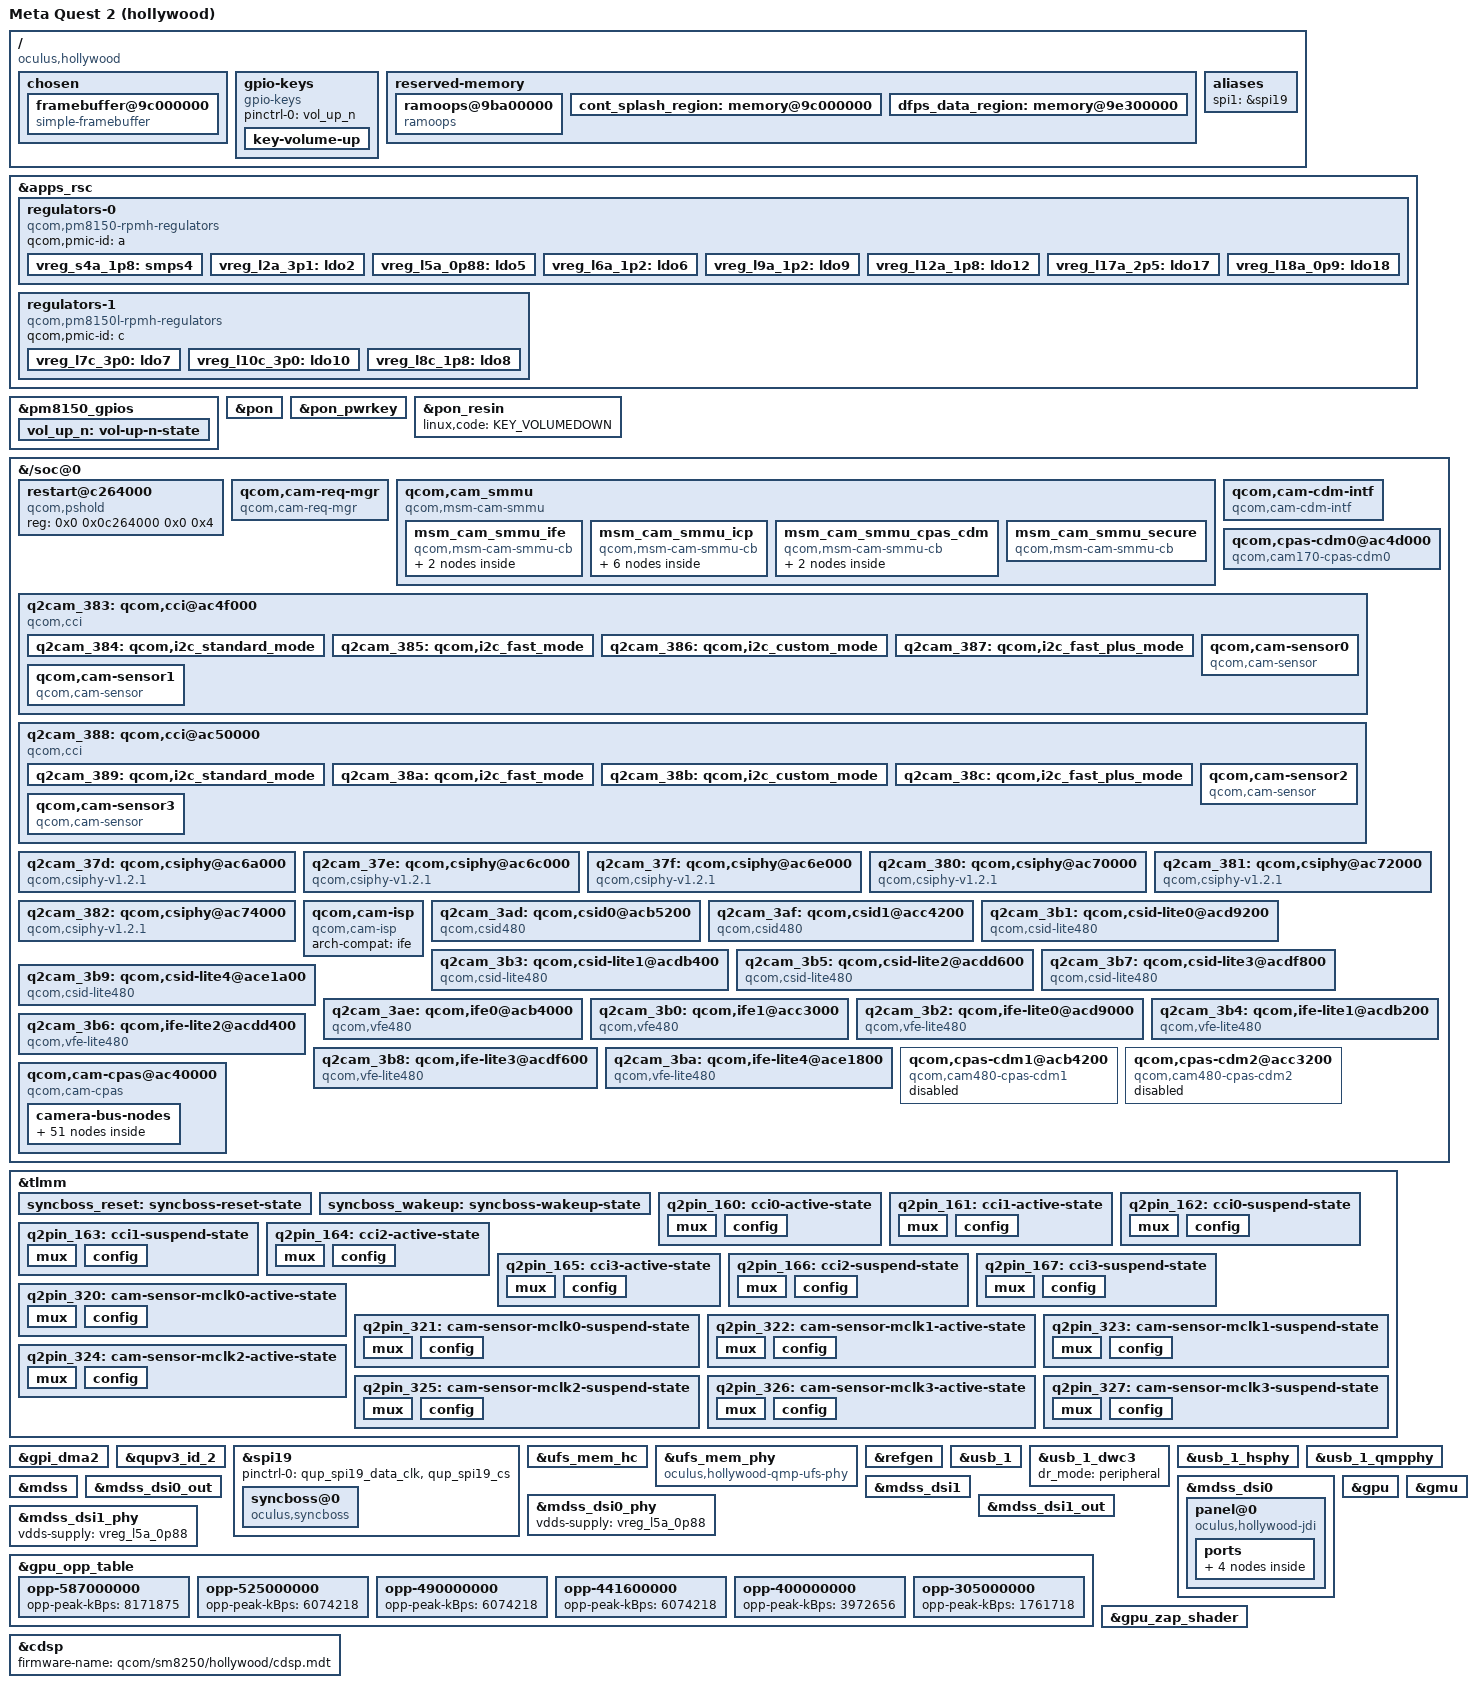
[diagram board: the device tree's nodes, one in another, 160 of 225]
// SPDX-License-Identifier: GPL-2.0-only
/*
 * Meta Quest 2 (hollywood), stage 1: storage, USB device mode, keys and the RAM console.
 * Display, GPU and the rest stay off, as the bootloader left them.
 * Supplies, carve-outs and GPIOs from the Quest 2's stock tree (board "Hollywood (DVT)", 0x40 0x11).
 */

/dts-v1/;

#include <dt-bindings/arm/qcom,ids.h>
#include <dt-bindings/clock/qcom,dispcc-sm8250.h>
#include <dt-bindings/phy/phy.h>
#include <dt-bindings/firmware/qcom,scm.h>
#include <dt-bindings/input/input.h>
#include <dt-bindings/regulator/qcom,rpmh-regulator.h>
#include "sm8250.dtsi"
#include "pm8150.dtsi"
#include "sm8250-oculus-hollywood-dtbo-sink.dtsi"

/ {
	model = "Meta Quest 2 (hollywood)";
	compatible = "oculus,hollywood", "qcom,sm8250";
	chassis-type = "embedded";

	/* Meta's board overlay overwrites compatible and model; the kernel restores them from these. */
	quest2,compatible = "oculus,hollywood", "qcom,sm8250";
	quest2,model = "Meta Quest 2 (hollywood)";

	/* Base tree chosen by SoC revision; the board itself comes from Meta's dtbo. */
	qcom,msm-id = <QCOM_ID_SM8250 0x20001>;
	qcom,board-id = <0 0>;

	chosen {
		#address-cells = <2>;
		#size-cells = <2>;
		ranges;

		/* The bootloader's splash, still scanned out: the kernel console until the display driver runs. */
		framebuffer@9c000000 {
			compatible = "simple-framebuffer";
			reg = <0x0 0x9c000000 0x0 0x1b78000>;
			width = <1920>;
			height = <3664>;
			stride = <7680>;
			format = "a8r8g8b8";
		};
	};

	gpio-keys {
		compatible = "gpio-keys";
		pinctrl-names = "default";
		pinctrl-0 = <&vol_up_n>;

		key-volume-up {
			label = "volume_up";
			gpios = <&pm8150_gpios 6 GPIO_ACTIVE_LOW>;
			linux,code = <KEY_VOLUMEUP>;
			debounce-interval = <15>;
			linux,can-disable;
			wakeup-source;
		};
	};

	reserved-memory {
		/* Same place and size as Quest OS's ramoops. */
		ramoops@9ba00000 {
			compatible = "ramoops";
			reg = <0x0 0x9ba00000 0x0 0x90000>;
			record-size = <0x20000>;
			console-size = <0x40000>;
			pmsg-size = <0x20000>;
			no-map;
		};

		/* Splash framebuffer, still on screen at kernel start. */
		cont_splash_region: memory@9c000000 {
			reg = <0x0 0x9c000000 0x0 0x2300000>;
			no-map;
		};

		dfps_data_region: memory@9e300000 {
			reg = <0x0 0x9e300000 0x0 0x100000>;
			no-map;
		};
	};
};

&apps_rsc {
	regulators-0 {
		compatible = "qcom,pm8150-rpmh-regulators";
		qcom,pmic-id = "a";

		/* UFS and USB supplies, stock voltages. */
		vreg_s4a_1p8: smps4 {
			regulator-name = "vreg_s4a_1p8";
			regulator-min-microvolt = <1800000>;
			regulator-max-microvolt = <1920000>;
		};

		vreg_l2a_3p1: ldo2 {
			regulator-name = "vreg_l2a_3p1";
			regulator-min-microvolt = <3072000>;
			regulator-max-microvolt = <3072000>;
			regulator-initial-mode = <RPMH_REGULATOR_MODE_HPM>;
		};

		vreg_l5a_0p88: ldo5 {
			regulator-name = "vreg_l5a_0p88";
			regulator-min-microvolt = <880000>;
			regulator-max-microvolt = <880000>;
			regulator-initial-mode = <RPMH_REGULATOR_MODE_HPM>;
			/* shared by the UFS and DSI PHYs: a DSI probe error must not switch storage off */
			regulator-always-on;
			regulator-boot-on;
		};

		vreg_l6a_1p2: ldo6 {
			regulator-name = "vreg_l6a_1p2";
			regulator-min-microvolt = <1200000>;
			regulator-max-microvolt = <1200000>;
			regulator-initial-mode = <RPMH_REGULATOR_MODE_HPM>;
		};

		vreg_l9a_1p2: ldo9 {
			regulator-name = "vreg_l9a_1p2";
			regulator-min-microvolt = <1200000>;
			regulator-max-microvolt = <1200000>;
			regulator-initial-mode = <RPMH_REGULATOR_MODE_HPM>;
			/* shared by the UFS and DSI PHYs: a DSI probe error must not switch storage off */
			regulator-always-on;
			regulator-boot-on;
		};

		vreg_l12a_1p8: ldo12 {
			regulator-name = "vreg_l12a_1p8";
			regulator-min-microvolt = <1800000>;
			regulator-max-microvolt = <1800000>;
			regulator-initial-mode = <RPMH_REGULATOR_MODE_HPM>;
		};

		vreg_l17a_2p5: ldo17 {
			regulator-name = "vreg_l17a_2p5";
			/* UFS VCC: UFS 2.1 storage needs 2.7-3.6 V; Quest OS runs it at 2.95 V */
			regulator-min-microvolt = <2952000>;
			regulator-max-microvolt = <2952000>;
			regulator-initial-mode = <RPMH_REGULATOR_MODE_HPM>;
		};

		vreg_l18a_0p9: ldo18 {
			regulator-name = "vreg_l18a_0p9";
			regulator-min-microvolt = <800000>;
			regulator-max-microvolt = <920000>;
			regulator-initial-mode = <RPMH_REGULATOR_MODE_HPM>;
		};
	};

	regulators-1 {
		compatible = "qcom,pm8150l-rpmh-regulators";
		qcom,pmic-id = "c";

		/* SyncBoss' IMU and magnetometer, always on in Quest OS. */
		vreg_l7c_3p0: ldo7 {
			regulator-name = "vreg_l7c_3p0";
			regulator-min-microvolt = <3000000>;
			regulator-max-microvolt = <3000000>;
			regulator-initial-mode = <RPMH_REGULATOR_MODE_HPM>;
			regulator-always-on;
		};

		/* The tracking camera sensors' analog supply (cam_vana), 3.0 V as in Quest OS */
		vreg_l10c_3p0: ldo10 {
			regulator-name = "vreg_l10c_3p0";
			regulator-min-microvolt = <3000000>;
			regulator-max-microvolt = <3000000>;
			regulator-initial-mode = <RPMH_REGULATOR_MODE_HPM>;
		};

		vreg_l8c_1p8: ldo8 {
			regulator-name = "vreg_l8c_1p8";
			regulator-min-microvolt = <1800000>;
			regulator-max-microvolt = <1800000>;
			regulator-initial-mode = <RPMH_REGULATOR_MODE_HPM>;
			regulator-always-on;
		};
	};
};

&pm8150_gpios {
	vol_up_n: vol-up-n-state {
		pins = "gpio6";
		function = "normal";
		power-source = <1>;
		input-enable;
		bias-pull-up;
	};
};

&pon {
	mode-bootloader = <0x2>;
	mode-recovery = <0x1>;
};

&pon_pwrkey {
	status = "okay";
};

&pon_resin {
	linux,code = <KEY_VOLUMEDOWN>;
	status = "okay";
};

/* PS_HOLD reset, as Quest OS does it. */
&{/soc@0} {
	restart@c264000 {
		compatible = "qcom,pshold";
		reg = <0x0 0x0c264000 0x0 0x4>;
	};
};

&tlmm {
	/* GPIOs unused by Quest OS, plus the usual secure lines 28-31 and 40-43. */
	gpio-reserved-ranges = <28 4>, <40 4>, <68 7>, <76 1>, <78 1>, <82 6>, <90 1>, <92 2>,
			       <109 1>, <112 1>, <114 1>, <149 31>;

	syncboss_reset: syncboss-reset-state {
		pins = "gpio5";
		function = "gpio";
		drive-strength = <6>;
		output-low;
	};

	syncboss_wakeup: syncboss-wakeup-state {
		pins = "gpio4";
		function = "gpio";
		bias-pull-down;
		input-enable;
	};
};

/* SyncBoss: Meta's MCU for the IMU, proximity sensor and controller radio (firmware v59), as in Quest OS. */
/* SyncBoss on SPI bus 1 as in Quest OS: Meta's services open /sys/bus/spi/devices/spi1.0/control/te_timestamp. */
/ {
	aliases {
		spi1 = &spi19;
	};
};

&gpi_dma2 {
	status = "okay";
};

&qupv3_id_2 {
	status = "okay";
};

&spi19 {
	pinctrl-names = "default";
	pinctrl-0 = <&qup_spi19_data_clk &qup_spi19_cs>;
	status = "okay";

	syncboss@0 {
		compatible = "oculus,syncboss";
		reg = <0>;
		spi-max-frequency = <8000000>;
		spi-cpol;
		spi-cpha;
		pinctrl-names = "default";
		pinctrl-0 = <&syncboss_reset &syncboss_wakeup>;

		oculus,syncboss-reset-gpios = <&tlmm 5 GPIO_ACTIVE_HIGH>;
		oculus,syncboss-wakeup-gpios = <&tlmm 4 GPIO_ACTIVE_HIGH>;
		oculus,syncboss-timesync-gpios = <&tlmm 66 GPIO_ACTIVE_HIGH>;

		oculus,imu-core-supply = <&vreg_l7c_3p0>;
		oculus,imu-core-voltage-level = <3000000 3000000>;
		oculus,mag-core-supply = <&vreg_l8c_1p8>;
		oculus,mag-core-voltage-level = <1800000 1800000>;

		oculus,syncboss-has-prox;
		oculus,syncboss-use-fastpath;
		oculus,syncboss-has-wake-reasons;
		oculus,syncboss-has-seq-num-ioctl;
	};
};

&ufs_mem_hc {
	status = "okay";

	/* UFS 2.1 storage, gear 3 at most (as Quest OS runs it): the PHY gets its gear-3 tables. */
	limit-hs-gear = <3>;

	/* The storage chip's reset line (the SoC's UFS_RESET pin), pulsed before the link starts. */
	reset-gpios = <&tlmm 180 GPIO_ACTIVE_LOW>;

	vcc-supply = <&vreg_l17a_2p5>;
	vcc-max-microamp = <800000>;
	vccq-supply = <&vreg_l6a_1p2>;
	vccq-max-microamp = <800000>;
	vccq2-supply = <&vreg_s4a_1p8>;
	vccq2-max-microamp = <800000>;
};

&ufs_mem_phy {
	/* UFS 2.1 storage: Quest OS's PHY settings for gear 3 (upstream's are for UFS 3.x) */
	compatible = "oculus,hollywood-qmp-ufs-phy";
	status = "okay";

	vdda-phy-supply = <&vreg_l5a_0p88>;
	vdda-pll-supply = <&vreg_l9a_1p2>;
};

/* The PHYs' shared reference voltage stays on, as the bootloader left it. */
&refgen {
	regulator-always-on;
	regulator-boot-on;
};

&usb_1 {
	status = "okay";
};

/* Stage 1: USB device mode, network to the PC. */
&usb_1_dwc3 {
	dr_mode = "peripheral";
};

&usb_1_hsphy {
	status = "okay";

	vdda-pll-supply = <&vreg_l5a_0p88>;
	vdda18-supply = <&vreg_l12a_1p8>;
	vdda33-supply = <&vreg_l2a_3p1>;
};

&usb_1_qmpphy {
	status = "okay";

	vdda-phy-supply = <&vreg_l9a_1p2>;
	vdda-pll-supply = <&vreg_l18a_0p9>;
};

/* The JDI LCD: both eyes on one panel, two bonded DSI links with DSC. */
&mdss {
	status = "okay";
};

&mdss_dsi0 {
	vdda-supply = <&vreg_l9a_1p2>;
	qcom,dual-dsi-mode;
	qcom,master-dsi;
	status = "okay";

	panel@0 {
		compatible = "oculus,hollywood-jdi";
		reg = <0>;

		enable-gpios = <&tlmm 135 GPIO_ACTIVE_HIGH>;
		reset-gpios = <&tlmm 6 GPIO_ACTIVE_LOW>;

		ports {
			#address-cells = <1>;
			#size-cells = <0>;

			port@0 {
				reg = <0>;
				panel_in0: endpoint {
					remote-endpoint = <&mdss_dsi0_out>;
				};
			};

			port@1 {
				reg = <1>;
				panel_in1: endpoint {
					remote-endpoint = <&mdss_dsi1_out>;
				};
			};
		};
	};
};

&mdss_dsi0_out {
	remote-endpoint = <&panel_in0>;
	data-lanes = <0 1 2 3>;
};

&mdss_dsi0_phy {
	vdds-supply = <&vreg_l5a_0p88>;
	status = "okay";
};

&mdss_dsi1 {
	vdda-supply = <&vreg_l9a_1p2>;
	qcom,dual-dsi-mode;
	assigned-clocks = <&dispcc DISP_CC_MDSS_BYTE1_CLK_SRC>, <&dispcc DISP_CC_MDSS_PCLK1_CLK_SRC>;
	assigned-clock-parents = <&mdss_dsi0_phy DSI_BYTE_PLL_CLK>, <&mdss_dsi0_phy DSI_PIXEL_PLL_CLK>;
	status = "okay";
};

&mdss_dsi1_out {
	remote-endpoint = <&panel_in1>;
	data-lanes = <0 1 2 3>;
};

&mdss_dsi1_phy {
	vdds-supply = <&vreg_l5a_0p88>;
	status = "okay";
};

/* Adreno 650, at most 587 MHz. Memory bandwidth per speed from Quest OS's GPU bus table (ddr7 levels 11/9/7/3). */
&gpu {
	interconnects = <&gem_noc MASTER_GRAPHICS_3D 0 &mc_virt SLAVE_EBI_CH0 0>;
	interconnect-names = "gfx-mem";
	status = "okay";
};

&gmu {
	status = "okay";
};

&gpu_opp_table {
	/delete-node/ opp-670000000;

	opp-587000000 {
		opp-peak-kBps = <8171875>;
	};

	opp-525000000 {
		opp-peak-kBps = <6074218>;
	};

	opp-490000000 {
		opp-peak-kBps = <6074218>;
	};

	opp-441600000 {
		opp-peak-kBps = <6074218>;
	};

	opp-400000000 {
		opp-peak-kBps = <3972656>;
	};

	opp-305000000 {
		opp-peak-kBps = <1761718>;
	};
};

/* This headset's signed zap shader, from its modem partition. */
&gpu_zap_shader {
	firmware-name = "qcom/sm8250/hollywood/a650_zap.mdt";
};

/* The compute DSP (Meta's tracker runs on it), with this headset's own signed firmware from its modem partition. */
&cdsp {
	firmware-name = "qcom/sm8250/hollywood/cdsp.mdt";
	status = "okay";
};

/*
 * Qualcomm's Spectra camera (techpack/camera), nodes converted from Quest OS's own tree: clocks by name onto
 * mainline's gcc/camcc, GDSC supplies as camcc power domains, bus votes on the matching interconnect paths.
 * CPAS: camera power, clocks and bandwidth.
 */
&{/soc@0} {
		/* The request manager: the camera's root device (/dev/video0, media0) the other blocks register under */
		qcom,cam-req-mgr {
			compatible = "qcom,cam-req-mgr";
			status = "okay";
		};

		/* Camera SMMU context banks (IFE, ICP, CPAS CDM) on the apps SMMU with Quest OS's stream ids, and the CDM */
		qcom,cam_smmu {
			compatible = "qcom,msm-cam-smmu";
			status = "ok";
			msm_cam_smmu_ife {
				compatible = "qcom,msm-cam-smmu-cb";
				iommus = <&apps_smmu 0x800 0x400>, <&apps_smmu 0x801 0x400>, <&apps_smmu 0x840 0x400>, <&apps_smmu 0x841 0x400>, <&apps_smmu 0xc00 0x400>, <&apps_smmu 0xc01 0x400>, <&apps_smmu 0xc40 0x400>, <&apps_smmu 0xc41 0x400>;
				qcom,iommu-dma-addr-pool = <0x7400000 0xd8c00000>;
				label = "ife";
				qcom,iommu-faults = "non-fatal";
				q2cam_38d: iova-mem-map {
					iova-mem-region-io {
						iova-region-name = "io";
						iova-region-start = <0x7400000>;
						iova-region-len = <0xd8c00000>;
						iova-region-id = <0x3>;
						status = "ok";
					};
				};
			};
			msm_cam_smmu_icp {
				compatible = "qcom,msm-cam-smmu-cb";
				iommus = <&apps_smmu 0x20e2 0x400>, <&apps_smmu 0x24e2 0x400>, <&apps_smmu 0x2000 0x400>, <&apps_smmu 0x2001 0x400>, <&apps_smmu 0x2400 0x400>, <&apps_smmu 0x2401 0x400>, <&apps_smmu 0x2060 0x400>, <&apps_smmu 0x2061 0x400>, <&apps_smmu 0x2460 0x400>, <&apps_smmu 0x2461 0x400>, <&apps_smmu 0x2020 0x400>, <&apps_smmu 0x2021 0x400>, <&apps_smmu 0x2420 0x400>, <&apps_smmu 0x2421 0x400>;
				label = "icp";
				qcom,iommu-dma-addr-pool = <0x10c00000 0xee300000>;
				iova-region-discard = <0xdff00000 0x300000>;
				qcom,iommu-faults = "non-fatal";
				q2cam_38f: iova-mem-map {
					iova-mem-region-firmware {
						iova-region-name = "firmware";
						iova-region-start = <0x0>;
						iova-region-len = <0x500000>;
						iova-region-id = <0x0>;
						status = "ok";
					};
					iova-mem-region-shared {
						iova-region-name = "shared";
						iova-region-start = <0x7400000>;
						iova-region-len = <0x9600000>;
						iova-region-id = <0x1>;
						status = "ok";
					};
					iova-mem-region-secondary-heap {
						iova-region-name = "secheap";
						iova-region-start = <0x10a00000>;
						iova-region-len = <0x100000>;
						iova-region-id = <0x4>;
						status = "ok";
					};
					iova-mem-region-io {
						iova-region-name = "io";
						iova-region-start = <0x10c00000>;
						iova-region-len = <0xee300000>;
						iova-region-id = <0x3>;
						iova-region-discard = <0xdff00000 0x300000>;
						status = "ok";
					};
					iova-mem-qdss-region {
						iova-region-name = "qdss";
						iova-region-start = <0x10b00000>;
						iova-region-len = <0x100000>;
						iova-region-id = <0x5>;
						qdss-phy-addr = <0x16790000>;
						status = "ok";
					};
				};
			};
			msm_cam_smmu_cpas_cdm {
				compatible = "qcom,msm-cam-smmu-cb";
				iommus = <&apps_smmu 0x20c0 0x400>, <&apps_smmu 0x24c0 0x400>;
				label = "cpas-cdm0";
				qcom,iommu-dma-addr-pool = <0x7400000 0xd8c00000>;
				qcom,iommu-faults = "non-fatal";
				q2cam_390: iova-mem-map {
					iova-mem-region-io {
						iova-region-name = "io";
						iova-region-start = <0x7400000>;
						iova-region-len = <0xd8c00000>;
						iova-region-id = <0x3>;
						status = "ok";
					};
				};
			};
			/* The secure bank: no stream ids, only the handle the ISP manager looks up (secure mode unused) */
			msm_cam_smmu_secure {
				compatible = "qcom,msm-cam-smmu-cb";
				label = "cam-secure";
				qcom,secure-cb;
			};
		};
		qcom,cam-cdm-intf {
			compatible = "qcom,cam-cdm-intf";
			cell-index = <0x0>;
			label = "cam-cdm-intf";
			num-hw-cdm = <0x3>;
			cdm-client-names = "vfe", "vife";
			status = "ok";
		};
		qcom,cpas-cdm0@ac4d000 {
			cell-index = <0x0>;
			compatible = "qcom,cam170-cpas-cdm0";
			label = "cpas-cdm";
			reg = <0x0 0xac4d000 0x0 0x1000>;
			reg-names = "cpas-cdm";
			reg-cam-base = <0x4d000>;
			interrupts = <0x0 0x1cd 0x1>;
			interrupt-names = "cpas-cdm";
			regulator-names = "camss";
			clock-names = "cam_cc_cpas_slow_ahb_clk", "cam_cc_cpas_ahb_clk";
			clocks = <&camcc CAM_CC_SLOW_AHB_CLK_SRC>, <&camcc CAM_CC_CPAS_AHB_CLK>;
			clock-rates = <0x0 0x0>;
			clock-cntl-level = "svs";
			cdm-client-names = "ife";
			status = "ok";
			power-domains = <&camcc TITAN_TOP_GDSC>;
			power-domain-names = "camss";
		};

		/* CCI (camera I2C) with the four tracking camera sensors behind it, as Quest OS's tree has them */
		q2cam_383: qcom,cci@ac4f000 {
			cell-index = <0x0>;
			compatible = "qcom,cci";
			reg = <0x0 0xac4f000 0x0 0x1000>;
			reg-names = "cci";
			reg-cam-base = <0x4f000>;
			interrupt-names = "cci";
			interrupts = <0x0 0x1cc 0x1>;
			status = "ok";
			regulator-names = "gdscr";
			clocks = <&camcc CAM_CC_CCI_0_CLK_SRC>, <&camcc CAM_CC_CCI_0_CLK>;
			clock-names = "cci_0_clk_src", "cci_0_clk";
			src-clock-name = "cci_0_clk_src";
			clock-cntl-level = "lowsvs";
			clock-rates = <0x23c3460 0x0>;
			pinctrl-names = "cam_default", "cam_suspend";
			pinctrl-0 = <&q2pin_160 &q2pin_161>;
			pinctrl-1 = <&q2pin_162 &q2pin_163>;
			gpios = <&tlmm 101 0>, <&tlmm 102 0>, <&tlmm 103 0>, <&tlmm 104 0>;
			gpio-req-tbl-num = <0x0 0x1 0x2 0x3>;
			gpio-req-tbl-flags = <0x1 0x1 0x1 0x1>;
			gpio-req-tbl-label = "CCI_I2C_DATA0", "CCI_I2C_CLK0", "CCI_I2C_DATA1", "CCI_I2C_CLK1";
			power-domains = <&camcc TITAN_TOP_GDSC>;
			power-domain-names = "gdscr";
			q2cam_384: qcom,i2c_standard_mode {
				hw-thigh = <0xc9>;
				hw-tlow = <0xae>;
				hw-tsu-sto = <0xcc>;
				hw-tsu-sta = <0xe7>;
				hw-thd-dat = <0x16>;
				hw-thd-sta = <0xa2>;
				hw-tbuf = <0xe3>;
				hw-scl-stretch-en = <0x0>;
				hw-trdhld = <0x6>;
				hw-tsp = <0x3>;
				cci-clk-src = <0x23c3460>;
				status = "ok";
			};
			q2cam_385: qcom,i2c_fast_mode {
				hw-thigh = <0x26>;
				hw-tlow = <0x38>;
				hw-tsu-sto = <0x28>;
				hw-tsu-sta = <0x28>;
				hw-thd-dat = <0x16>;
				hw-thd-sta = <0x23>;
				hw-tbuf = <0x3e>;
				hw-scl-stretch-en = <0x0>;
				hw-trdhld = <0x6>;
				hw-tsp = <0x3>;
				cci-clk-src = <0x23c3460>;
				status = "ok";
			};
			q2cam_386: qcom,i2c_custom_mode {
				hw-thigh = <0x26>;
				hw-tlow = <0x38>;
				hw-tsu-sto = <0x28>;
				hw-tsu-sta = <0x28>;
				hw-thd-dat = <0x16>;
				hw-thd-sta = <0x23>;
				hw-tbuf = <0x3e>;
				hw-scl-stretch-en = <0x1>;
				hw-trdhld = <0x6>;
				hw-tsp = <0x3>;
				cci-clk-src = <0x23c3460>;
				status = "ok";
			};
			q2cam_387: qcom,i2c_fast_plus_mode {
				hw-thigh = <0x10>;
				hw-tlow = <0x16>;
				hw-tsu-sto = <0x11>;
				hw-tsu-sta = <0x12>;
				hw-thd-dat = <0x10>;
				hw-thd-sta = <0xf>;
				hw-tbuf = <0x18>;
				hw-scl-stretch-en = <0x0>;
				hw-trdhld = <0x3>;
				hw-tsp = <0x3>;
				cci-clk-src = <0x23c3460>;
				status = "ok";
			};
			qcom,cam-sensor0 {
				cell-index = <0x0>;
				compatible = "qcom,cam-sensor";
				csiphy-sd-index = <0x2>;
				sensor-position-roll = <0x5a>;
				sensor-position-pitch = <0x0>;
				sensor-position-yaw = <0xb4>;
				cam_vana-supply = <&vreg_l10c_3p0>;
				cam_vio-supply = <&vreg_s4a_1p8>;
				regulator-names = "cam_vana", "cam_vio", "cam_clk";
				rgltr-cntrl-support;
				pwm-switch;
				rgltr-min-voltage = <0x2dc6c0 0x1b7740 0x0>;
				rgltr-max-voltage = <0x2dc6c0 0x1b7740 0x0>;
				rgltr-load-current = <0x1d4c0 0x13880 0x0>;
				gpio-no-mux = <0x0>;
				pinctrl-names = "cam_default", "cam_suspend";
				pinctrl-0 = <&q2pin_324>;
				pinctrl-1 = <&q2pin_325>;
				gpios = <&tlmm 96 0>;
				gpio-req-tbl-num = <0x0>;
				gpio-req-tbl-flags = <0x1>;
				gpio-req-tbl-label = "CAMIF_MCLK2";
				sensor-mode = <0x0>;
				cci-master = <0x0>;
				status = "ok";
				clocks = <&camcc CAM_CC_MCLK2_CLK>;
				clock-names = "cam_clk";
				clock-cntl-level = "turbo";
				clock-rates = <0x16e3600>;
				power-domains = <&camcc TITAN_TOP_GDSC>;
				power-domain-names = "cam_clk";
			};
			qcom,cam-sensor1 {
				cell-index = <0x1>;
				compatible = "qcom,cam-sensor";
				csiphy-sd-index = <0x1>;
				sensor-position-roll = <0x5a>;
				sensor-position-pitch = <0x0>;
				sensor-position-yaw = <0xb4>;
				cam_vana-supply = <&vreg_l10c_3p0>;
				cam_vio-supply = <&vreg_s4a_1p8>;
				regulator-names = "cam_vana", "cam_vio", "cam_clk";
				rgltr-cntrl-support;
				pwm-switch;
				rgltr-min-voltage = <0x2dc6c0 0x1b7740 0x0>;
				rgltr-max-voltage = <0x2dc6c0 0x1b7740 0x0>;
				rgltr-load-current = <0x1d4c0 0x13880 0x0>;
				gpio-no-mux = <0x0>;
				pinctrl-names = "cam_default", "cam_suspend";
				pinctrl-0 = <&q2pin_326>;
				pinctrl-1 = <&q2pin_327>;
				gpios = <&tlmm 95 0>;
				gpio-req-tbl-num = <0x0>;
				gpio-req-tbl-flags = <0x1>;
				gpio-req-tbl-label = "CAMIF_MCLK1";
				sensor-mode = <0x0>;
				cci-master = <0x1>;
				status = "ok";
				clocks = <&camcc CAM_CC_MCLK1_CLK>;
				clock-names = "cam_clk";
				clock-cntl-level = "turbo";
				clock-rates = <0x16e3600>;
				power-domains = <&camcc TITAN_TOP_GDSC>;
				power-domain-names = "cam_clk";
			};
		};
		q2cam_388: qcom,cci@ac50000 {
			cell-index = <0x1>;
			compatible = "qcom,cci";
			reg = <0x0 0xac50000 0x0 0x1000>;
			reg-names = "cci";
			reg-cam-base = <0x50000>;
			interrupt-names = "cci";
			interrupts = <0x0 0x10f 0x1>;
			status = "ok";
			regulator-names = "gdscr";
			clocks = <&camcc CAM_CC_CCI_1_CLK_SRC>, <&camcc CAM_CC_CCI_1_CLK>;
			clock-names = "cci_1_clk_src", "cci_1_clk";
			src-clock-name = "cci_1_clk_src";
			clock-cntl-level = "lowsvs";
			clock-rates = <0x23c3460 0x0>;
			pinctrl-names = "cam_default", "cam_suspend";
			pinctrl-0 = <&q2pin_164 &q2pin_165>;
			pinctrl-1 = <&q2pin_166 &q2pin_167>;
			gpios = <&tlmm 105 0>, <&tlmm 106 0>, <&tlmm 107 0>, <&tlmm 108 0>;
			gpio-req-tbl-num = <0x0 0x1 0x2 0x3>;
			gpio-req-tbl-flags = <0x1 0x1 0x1 0x1>;
			gpio-req-tbl-label = "CCI_I2C_DATA2", "CCI_I2C_CLK2", "CCI_I2C_DATA3", "CCI_I2C_CLK3";
			power-domains = <&camcc TITAN_TOP_GDSC>;
			power-domain-names = "gdscr";
			q2cam_389: qcom,i2c_standard_mode {
				hw-thigh = <0xc9>;
				hw-tlow = <0xae>;
				hw-tsu-sto = <0xcc>;
				hw-tsu-sta = <0xe7>;
				hw-thd-dat = <0x16>;
				hw-thd-sta = <0xa2>;
				hw-tbuf = <0xe3>;
				hw-scl-stretch-en = <0x0>;
				hw-trdhld = <0x6>;
				hw-tsp = <0x3>;
				cci-clk-src = <0x23c3460>;
				status = "ok";
			};
			q2cam_38a: qcom,i2c_fast_mode {
				hw-thigh = <0x26>;
				hw-tlow = <0x38>;
				hw-tsu-sto = <0x28>;
				hw-tsu-sta = <0x28>;
				hw-thd-dat = <0x16>;
				hw-thd-sta = <0x23>;
				hw-tbuf = <0x3e>;
				hw-scl-stretch-en = <0x0>;
				hw-trdhld = <0x6>;
				hw-tsp = <0x3>;
				cci-clk-src = <0x23c3460>;
				status = "ok";
			};
			q2cam_38b: qcom,i2c_custom_mode {
				hw-thigh = <0x26>;
				hw-tlow = <0x38>;
				hw-tsu-sto = <0x28>;
				hw-tsu-sta = <0x28>;
				hw-thd-dat = <0x16>;
				hw-thd-sta = <0x23>;
				hw-tbuf = <0x3e>;
				hw-scl-stretch-en = <0x1>;
				hw-trdhld = <0x6>;
				hw-tsp = <0x3>;
				cci-clk-src = <0x23c3460>;
				status = "ok";
			};
			q2cam_38c: qcom,i2c_fast_plus_mode {
				hw-thigh = <0x10>;
				hw-tlow = <0x16>;
				hw-tsu-sto = <0x11>;
				hw-tsu-sta = <0x12>;
				hw-thd-dat = <0x10>;
				hw-thd-sta = <0xf>;
				hw-tbuf = <0x18>;
				hw-scl-stretch-en = <0x0>;
				hw-trdhld = <0x3>;
				hw-tsp = <0x3>;
				cci-clk-src = <0x23c3460>;
				status = "ok";
			};
			qcom,cam-sensor2 {
				cell-index = <0x2>;
				compatible = "qcom,cam-sensor";
				csiphy-sd-index = <0x0>;
				sensor-position-roll = <0x10e>;
				sensor-position-pitch = <0x0>;
				sensor-position-yaw = <0x0>;
				cam_vana-supply = <&vreg_l10c_3p0>;
				cam_vio-supply = <&vreg_s4a_1p8>;
				regulator-names = "cam_vana", "cam_vio", "cam_clk";
				rgltr-cntrl-support;
				pwm-switch;
				rgltr-min-voltage = <0x2dc6c0 0x1b7740 0x0>;
				rgltr-max-voltage = <0x2dc6c0 0x1b7740 0x0>;
				rgltr-load-current = <0x1d4c0 0x13880 0x0>;
				gpio-no-mux = <0x0>;
				pinctrl-names = "cam_default", "cam_suspend";
				pinctrl-0 = <&q2pin_320>;
				pinctrl-1 = <&q2pin_321>;
				gpios = <&tlmm 94 0>;
				gpio-req-tbl-num = <0x0>;
				gpio-req-tbl-flags = <0x1>;
				gpio-req-tbl-label = "CAMIF_MCLK0";
				sensor-mode = <0x0>;
				cci-master = <0x0>;
				status = "ok";
				clocks = <&camcc CAM_CC_MCLK0_CLK>;
				clock-names = "cam_clk";
				clock-cntl-level = "turbo";
				clock-rates = <0x16e3600>;
				power-domains = <&camcc TITAN_TOP_GDSC>;
				power-domain-names = "cam_clk";
			};
			qcom,cam-sensor3 {
				cell-index = <0x3>;
				compatible = "qcom,cam-sensor";
				csiphy-sd-index = <0x3>;
				sensor-position-roll = <0x10e>;
				sensor-position-pitch = <0x0>;
				sensor-position-yaw = <0x0>;
				cam_vana-supply = <&vreg_l10c_3p0>;
				cam_vio-supply = <&vreg_s4a_1p8>;
				regulator-names = "cam_vana", "cam_vio", "cam_clk";
				rgltr-cntrl-support;
				rgltr-min-voltage = <0x2dc6c0 0x1b7740 0x0>;
				rgltr-max-voltage = <0x2dc6c0 0x1b7740 0x0>;
				rgltr-load-current = <0x1d4c0 0x13880 0x0>;
				gpio-no-mux = <0x0>;
				pinctrl-names = "cam_default", "cam_suspend";
				pinctrl-0 = <&q2pin_322>;
				pinctrl-1 = <&q2pin_323>;
				gpios = <&tlmm 97 0>;
				gpio-req-tbl-num = <0x0>;
				gpio-req-tbl-flags = <0x1>;
				gpio-req-tbl-label = "CAMIF_MCLK3";
				sensor-mode = <0x0>;
				cci-master = <0x1>;
				status = "ok";
				clocks = <&camcc CAM_CC_MCLK3_CLK>;
				clock-names = "cam_clk";
				clock-cntl-level = "turbo";
				clock-rates = <0x16e3600>;
				power-domains = <&camcc TITAN_TOP_GDSC>;
				power-domain-names = "cam_clk";
			};
		};

		/* CSIPHYs, the ISP (IFE0/1 + five IFE-lites with their CSIDs) and the IFE CDMs */
		q2cam_37d: qcom,csiphy@ac6a000 {
			cell-index = <0x0>;
			compatible = "qcom,csiphy-v1.2.1", "qcom,csiphy";
			reg = <0x0 0xac6a000 0x0 0x2000>;
			reg-names = "csiphy";
			reg-cam-base = <0x6a000>;
			interrupts = <0x0 0x1dd 0x1>;
			interrupt-names = "csiphy";
			refgen-supply = <&refgen>;
			regulator-names = "gdscr", "refgen";
			csi-vdd-voltage = <0x124f80>;
			mipi-csi-vdd-supply = <&vreg_l9a_1p2>;
			clocks = <&camcc CAM_CC_CPHY_RX_CLK_SRC>, <&camcc CAM_CC_CSIPHY0_CLK>, <&camcc CAM_CC_CSI0PHYTIMER_CLK_SRC>, <&camcc CAM_CC_CSI0PHYTIMER_CLK>;
			clock-names = "cphy_rx_clk_src", "csiphy0_clk", "csi0phytimer_clk_src", "csi0phytimer_clk";
			src-clock-name = "csi0phytimer_clk_src";
			clock-cntl-level = "turbo";
			clock-rates = <0x17d78400 0x0 0x11e1a300 0x0>;
			status = "ok";
			power-domains = <&camcc TITAN_TOP_GDSC>;
			power-domain-names = "gdscr";
		};
		q2cam_37e: qcom,csiphy@ac6c000 {
			cell-index = <0x1>;
			compatible = "qcom,csiphy-v1.2.1", "qcom,csiphy";
			reg = <0x0 0xac6c000 0x0 0x2000>;
			reg-names = "csiphy";
			reg-cam-base = <0x6c000>;
			interrupts = <0x0 0x1de 0x1>;
			interrupt-names = "csiphy";
			refgen-supply = <&refgen>;
			regulator-names = "gdscr", "refgen";
			csi-vdd-voltage = <0x124f80>;
			mipi-csi-vdd-supply = <&vreg_l9a_1p2>;
			clocks = <&camcc CAM_CC_CPHY_RX_CLK_SRC>, <&camcc CAM_CC_CSIPHY1_CLK>, <&camcc CAM_CC_CSI1PHYTIMER_CLK_SRC>, <&camcc CAM_CC_CSI1PHYTIMER_CLK>;
			clock-names = "cphy_rx_clk_src", "csiphy1_clk", "csi1phytimer_clk_src", "csi1phytimer_clk";
			src-clock-name = "csi1phytimer_clk_src";
			clock-cntl-level = "turbo";
			clock-rates = <0x17d78400 0x0 0x11e1a300 0x0>;
			status = "ok";
			power-domains = <&camcc TITAN_TOP_GDSC>;
			power-domain-names = "gdscr";
		};
		q2cam_37f: qcom,csiphy@ac6e000 {
			cell-index = <0x2>;
			compatible = "qcom,csiphy-v1.2.1", "qcom,csiphy";
			reg = <0x0 0xac6e000 0x0 0x2000>;
			reg-names = "csiphy";
			reg-cam-base = <0x6e000>;
			interrupts = <0x0 0x1df 0x1>;
			interrupt-names = "csiphy";
			refgen-supply = <&refgen>;
			regulator-names = "gdscr", "refgen";
			csi-vdd-voltage = <0x124f80>;
			mipi-csi-vdd-supply = <&vreg_l9a_1p2>;
			clocks = <&camcc CAM_CC_CPHY_RX_CLK_SRC>, <&camcc CAM_CC_CSIPHY2_CLK>, <&camcc CAM_CC_CSI2PHYTIMER_CLK_SRC>, <&camcc CAM_CC_CSI2PHYTIMER_CLK>;
			clock-names = "cphy_rx_clk_src", "csiphy2_clk", "csi2phytimer_clk_src", "csi2phytimer_clk";
			src-clock-name = "csi2phytimer_clk_src";
			clock-cntl-level = "turbo";
			clock-rates = <0x17d78400 0x0 0x11e1a300 0x0>;
			status = "ok";
			power-domains = <&camcc TITAN_TOP_GDSC>;
			power-domain-names = "gdscr";
		};
		q2cam_380: qcom,csiphy@ac70000 {
			cell-index = <0x3>;
			compatible = "qcom,csiphy-v1.2.1", "qcom,csiphy";
			reg = <0x0 0xac70000 0x0 0x2000>;
			reg-names = "csiphy";
			reg-cam-base = <0x70000>;
			interrupts = <0x0 0x1c0 0x1>;
			interrupt-names = "csiphy";
			refgen-supply = <&refgen>;
			regulator-names = "gdscr", "refgen";
			csi-vdd-voltage = <0x124f80>;
			mipi-csi-vdd-supply = <&vreg_l9a_1p2>;
			clocks = <&camcc CAM_CC_CPHY_RX_CLK_SRC>, <&camcc CAM_CC_CSIPHY3_CLK>, <&camcc CAM_CC_CSI3PHYTIMER_CLK_SRC>, <&camcc CAM_CC_CSI3PHYTIMER_CLK>;
			clock-names = "cphy_rx_clk_src", "csiphy3_clk", "csi3phytimer_clk_src", "csi3phytimer_clk";
			src-clock-name = "csi3phytimer_clk_src";
			clock-cntl-level = "turbo";
			clock-rates = <0x17d78400 0x0 0x11e1a300 0x0>;
			status = "ok";
			power-domains = <&camcc TITAN_TOP_GDSC>;
			power-domain-names = "gdscr";
		};
		q2cam_381: qcom,csiphy@ac72000 {
			cell-index = <0x4>;
			compatible = "qcom,csiphy-v1.2.1", "qcom,csiphy";
			reg = <0x0 0xac72000 0x0 0x2000>;
			reg-names = "csiphy";
			reg-cam-base = <0x72000>;
			interrupts = <0x0 0x56 0x1>;
			interrupt-names = "csiphy";
			refgen-supply = <&refgen>;
			regulator-names = "gdscr", "refgen";
			csi-vdd-voltage = <0x124f80>;
			mipi-csi-vdd-supply = <&vreg_l9a_1p2>;
			clocks = <&camcc CAM_CC_CPHY_RX_CLK_SRC>, <&camcc CAM_CC_CSIPHY4_CLK>, <&camcc CAM_CC_CSI4PHYTIMER_CLK_SRC>, <&camcc CAM_CC_CSI4PHYTIMER_CLK>;
			clock-names = "cphy_rx_clk_src", "csiphy4_clk", "csi4phytimer_clk_src", "csi4phytimer_clk";
			src-clock-name = "csi4phytimer_clk_src";
			clock-cntl-level = "turbo";
			clock-rates = <0x17d78400 0x0 0x11e1a300 0x0>;
			status = "ok";
			power-domains = <&camcc TITAN_TOP_GDSC>;
			power-domain-names = "gdscr";
		};
		q2cam_382: qcom,csiphy@ac74000 {
			cell-index = <0x5>;
			compatible = "qcom,csiphy-v1.2.1", "qcom,csiphy";
			reg = <0x0 0xac74000 0x0 0x2000>;
			reg-names = "csiphy";
			reg-cam-base = <0x74000>;
			interrupts = <0x0 0x59 0x1>;
			interrupt-names = "csiphy";
			refgen-supply = <&refgen>;
			regulator-names = "gdscr", "refgen";
			csi-vdd-voltage = <0x124f80>;
			mipi-csi-vdd-supply = <&vreg_l9a_1p2>;
			clocks = <&camcc CAM_CC_CPHY_RX_CLK_SRC>, <&camcc CAM_CC_CSIPHY5_CLK>, <&camcc CAM_CC_CSI5PHYTIMER_CLK_SRC>, <&camcc CAM_CC_CSI5PHYTIMER_CLK>;
			clock-names = "cphy_rx_clk_src", "csiphy5_clk", "csi5phytimer_clk_src", "csi5phytimer_clk";
			src-clock-name = "csi5phytimer_clk_src";
			clock-cntl-level = "turbo";
			clock-rates = <0x17d78400 0x0 0x11e1a300 0x0>;
			status = "ok";
			power-domains = <&camcc TITAN_TOP_GDSC>;
			power-domain-names = "gdscr";
		};
		qcom,cam-isp {
			compatible = "qcom,cam-isp";
			arch-compat = "ife";
			status = "ok";
		};
		q2cam_3ad: qcom,csid0@acb5200 {
			cell-index = <0x0>;
			compatible = "qcom,csid480";
			reg-names = "csid";
			reg = <0x0 0xacb5200 0x0 0x1000>;
			reg-cam-base = <0xb5200>;
			interrupt-names = "csid";
			interrupts = <0x0 0x1d0 0x1>;
			regulator-names = "camss", "ife0";
			clock-names = "ife_csid_clk_src", "ife_csid_clk", "cphy_rx_clk_src", "ife_cphy_rx_clk", "ife_clk_src", "ife_clk", "ife_0_areg", "ife_0_ahb", "ife_axi_clk";
			clocks = <&camcc CAM_CC_IFE_0_CSID_CLK_SRC>, <&camcc CAM_CC_IFE_0_CSID_CLK>, <&camcc CAM_CC_CPHY_RX_CLK_SRC>, <&camcc CAM_CC_IFE_0_CPHY_RX_CLK>, <&camcc CAM_CC_IFE_0_CLK_SRC>, <&camcc CAM_CC_IFE_0_CLK>, <&camcc CAM_CC_IFE_0_AREG_CLK>, <&camcc CAM_CC_IFE_0_AHB_CLK>, <&camcc CAM_CC_IFE_0_AXI_CLK>;
			clock-rates = <0x17d78400 0x0 0x17d78400 0x0 0x14dc9380 0x0 0x5f5e100 0x0 0x0 0x17d78400 0x0 0x17d78400 0x0 0x1c4fecc0 0x0 0xbebc200 0x0 0x0 0x17d78400 0x0 0x17d78400 0x0 0x22551000 0x0 0x11e1a300 0x0 0x0 0x17d78400 0x0 0x17d78400 0x0 0x2aea5400 0x0 0x17d78400 0x0 0x0>;
			clock-cntl-level = "lowsvs", "svs", "svs_l1", "turbo";
			src-clock-name = "ife_csid_clk_src";
			clock-control-debugfs = "true";
			status = "ok";
			power-domains = <&camcc TITAN_TOP_GDSC>, <&camcc IFE_0_GDSC>;
			power-domain-names = "camss", "ife0";
		};
		q2cam_3af: qcom,csid1@acc4200 {
			cell-index = <0x1>;
			compatible = "qcom,csid480";
			reg-names = "csid";
			reg = <0x0 0xacc4200 0x0 0x1000>;
			reg-cam-base = <0xc4200>;
			interrupt-names = "csid";
			interrupts = <0x0 0x1d2 0x1>;
			regulator-names = "camss", "ife1";
			clock-names = "ife_csid_clk_src", "ife_csid_clk", "cphy_rx_clk_src", "ife_cphy_rx_clk", "ife_clk_src", "ife_clk", "ife_1_areg", "ife_1_ahb", "ife_axi_clk";
			clocks = <&camcc CAM_CC_IFE_1_CSID_CLK_SRC>, <&camcc CAM_CC_IFE_1_CSID_CLK>, <&camcc CAM_CC_CPHY_RX_CLK_SRC>, <&camcc CAM_CC_IFE_1_CPHY_RX_CLK>, <&camcc CAM_CC_IFE_1_CLK_SRC>, <&camcc CAM_CC_IFE_1_CLK>, <&camcc CAM_CC_IFE_1_AREG_CLK>, <&camcc CAM_CC_IFE_1_AHB_CLK>, <&camcc CAM_CC_IFE_1_AXI_CLK>;
			clock-rates = <0x17d78400 0x0 0x17d78400 0x0 0x14dc9380 0x0 0x5f5e100 0x0 0x0 0x17d78400 0x0 0x17d78400 0x0 0x1c4fecc0 0x0 0xbebc200 0x0 0x0 0x17d78400 0x0 0x17d78400 0x0 0x22551000 0x0 0x11e1a300 0x0 0x0 0x17d78400 0x0 0x17d78400 0x0 0x2aea5400 0x0 0x17d78400 0x0 0x0>;
			clock-cntl-level = "lowsvs", "svs", "svs_l1", "turbo";
			src-clock-name = "ife_csid_clk_src";
			clock-control-debugfs = "true";
			status = "ok";
			power-domains = <&camcc TITAN_TOP_GDSC>, <&camcc IFE_1_GDSC>;
			power-domain-names = "camss", "ife1";
		};
		q2cam_3b1: qcom,csid-lite0@acd9200 {
			cell-index = <0x2>;
			compatible = "qcom,csid-lite480";
			reg-names = "csid-lite";
			reg = <0x0 0xacd9200 0x0 0x1000>;
			reg-cam-base = <0xd9200>;
			interrupt-names = "csid-lite";
			interrupts = <0x0 0x1d4 0x1>;
			regulator-names = "camss";
			clock-names = "ife_csid_clk_src", "ife_csid_clk", "cphy_rx_clk_src", "ife_cphy_rx_clk", "ife_clk_src", "ife_lite_ahb", "ife_clk";
			clocks = <&camcc CAM_CC_IFE_LITE_CSID_CLK_SRC>, <&camcc CAM_CC_IFE_LITE_CSID_CLK>, <&camcc CAM_CC_CPHY_RX_CLK_SRC>, <&camcc CAM_CC_IFE_LITE_CPHY_RX_CLK>, <&camcc CAM_CC_IFE_LITE_CLK_SRC>, <&camcc CAM_CC_IFE_LITE_AHB_CLK>, <&camcc CAM_CC_IFE_LITE_CLK>;
			clock-rates = <0x17d78400 0x0 0x0 0x0 0x17d78400 0x0 0x0 0x17d78400 0x0 0x0 0x0 0x1c9c3800 0x0 0x0 0x17d78400 0x0 0x0 0x0 0x1c9c3800 0x0 0x0 0x17d78400 0x0 0x0 0x0 0x1c9c3800 0x0 0x0>;
			clock-cntl-level = "lowsvs", "svs", "svs_l1", "turbo";
			src-clock-name = "ife_csid_clk_src";
			clock-control-debugfs = "true";
			status = "ok";
			power-domains = <&camcc TITAN_TOP_GDSC>;
			power-domain-names = "camss";
		};
		q2cam_3b3: qcom,csid-lite1@acdb400 {
			cell-index = <0x3>;
			compatible = "qcom,csid-lite480";
			reg-names = "csid-lite";
			reg = <0x0 0xacdb400 0x0 0x1000>;
			reg-cam-base = <0xdb400>;
			interrupt-names = "csid-lite";
			interrupts = <0x0 0x167 0x1>;
			regulator-names = "camss";
			clock-names = "ife_csid_clk_src", "ife_csid_clk", "cphy_rx_clk_src", "ife_cphy_rx_clk", "ife_clk_src", "ife_lite_ahb", "ife_clk";
			clocks = <&camcc CAM_CC_IFE_LITE_CSID_CLK_SRC>, <&camcc CAM_CC_IFE_LITE_CSID_CLK>, <&camcc CAM_CC_CPHY_RX_CLK_SRC>, <&camcc CAM_CC_IFE_LITE_CPHY_RX_CLK>, <&camcc CAM_CC_IFE_LITE_CLK_SRC>, <&camcc CAM_CC_IFE_LITE_AHB_CLK>, <&camcc CAM_CC_IFE_LITE_CLK>;
			clock-rates = <0x17d78400 0x0 0x0 0x0 0x17d78400 0x0 0x0 0x17d78400 0x0 0x0 0x0 0x1c9c3800 0x0 0x0 0x17d78400 0x0 0x0 0x0 0x1c9c3800 0x0 0x0 0x17d78400 0x0 0x0 0x0 0x1c9c3800 0x0 0x0>;
			clock-cntl-level = "lowsvs", "svs", "svs_l1", "turbo";
			src-clock-name = "ife_csid_clk_src";
			clock-control-debugfs = "true";
			status = "ok";
			power-domains = <&camcc TITAN_TOP_GDSC>;
			power-domain-names = "camss";
		};
		q2cam_3b5: qcom,csid-lite2@acdd600 {
			cell-index = <0x4>;
			compatible = "qcom,csid-lite480";
			reg-names = "csid-lite";
			reg = <0x0 0xacdd600 0x0 0x1000>;
			reg-cam-base = <0xdd600>;
			interrupt-names = "csid-lite";
			interrupts = <0x0 0x1c1 0x1>;
			regulator-names = "camss";
			clock-names = "ife_csid_clk_src", "ife_csid_clk", "cphy_rx_clk_src", "ife_cphy_rx_clk", "ife_clk_src", "ife_lite_ahb", "ife_clk";
			clocks = <&camcc CAM_CC_IFE_LITE_CSID_CLK_SRC>, <&camcc CAM_CC_IFE_LITE_CSID_CLK>, <&camcc CAM_CC_CPHY_RX_CLK_SRC>, <&camcc CAM_CC_IFE_LITE_CPHY_RX_CLK>, <&camcc CAM_CC_IFE_LITE_CLK_SRC>, <&camcc CAM_CC_IFE_LITE_AHB_CLK>, <&camcc CAM_CC_IFE_LITE_CLK>;
			clock-rates = <0x17d78400 0x0 0x0 0x0 0x17d78400 0x0 0x0 0x17d78400 0x0 0x0 0x0 0x1c9c3800 0x0 0x0 0x17d78400 0x0 0x0 0x0 0x1c9c3800 0x0 0x0 0x17d78400 0x0 0x0 0x0 0x1c9c3800 0x0 0x0>;
			clock-cntl-level = "lowsvs", "svs", "svs_l1", "turbo";
			src-clock-name = "ife_csid_clk_src";
			clock-control-debugfs = "true";
			status = "ok";
			power-domains = <&camcc TITAN_TOP_GDSC>;
			power-domain-names = "camss";
		};
		q2cam_3b7: qcom,csid-lite3@acdf800 {
			cell-index = <0x5>;
			compatible = "qcom,csid-lite480";
			reg-names = "csid-lite";
			reg = <0x0 0xacdf800 0x0 0x1000>;
			reg-cam-base = <0xdf800>;
			interrupt-names = "csid-lite";
			interrupts = <0x0 0x1c3 0x1>;
			regulator-names = "camss";
			clock-names = "ife_csid_clk_src", "ife_csid_clk", "cphy_rx_clk_src", "ife_cphy_rx_clk", "ife_clk_src", "ife_lite_ahb", "ife_clk";
			clocks = <&camcc CAM_CC_IFE_LITE_CSID_CLK_SRC>, <&camcc CAM_CC_IFE_LITE_CSID_CLK>, <&camcc CAM_CC_CPHY_RX_CLK_SRC>, <&camcc CAM_CC_IFE_LITE_CPHY_RX_CLK>, <&camcc CAM_CC_IFE_LITE_CLK_SRC>, <&camcc CAM_CC_IFE_LITE_AHB_CLK>, <&camcc CAM_CC_IFE_LITE_CLK>;
			clock-rates = <0x17d78400 0x0 0x0 0x0 0x17d78400 0x0 0x0 0x17d78400 0x0 0x0 0x0 0x1c9c3800 0x0 0x0 0x17d78400 0x0 0x0 0x0 0x1c9c3800 0x0 0x0 0x17d78400 0x0 0x0 0x0 0x1c9c3800 0x0 0x0>;
			clock-cntl-level = "lowsvs", "svs", "svs_l1", "turbo";
			src-clock-name = "ife_csid_clk_src";
			clock-control-debugfs = "true";
			status = "ok";
			power-domains = <&camcc TITAN_TOP_GDSC>;
			power-domain-names = "camss";
		};
		q2cam_3b9: qcom,csid-lite4@ace1a00 {
			cell-index = <0x6>;
			compatible = "qcom,csid-lite480";
			reg-names = "csid-lite";
			reg = <0x0 0xace1a00 0x0 0x1000>;
			reg-cam-base = <0xe1a00>;
			interrupt-names = "csid-lite";
			interrupts = <0x0 0x1c5 0x1>;
			regulator-names = "camss";
			clock-names = "ife_csid_clk_src", "ife_csid_clk", "cphy_rx_clk_src", "ife_cphy_rx_clk", "ife_clk_src", "ife_lite_ahb", "ife_clk";
			clocks = <&camcc CAM_CC_IFE_LITE_CSID_CLK_SRC>, <&camcc CAM_CC_IFE_LITE_CSID_CLK>, <&camcc CAM_CC_CPHY_RX_CLK_SRC>, <&camcc CAM_CC_IFE_LITE_CPHY_RX_CLK>, <&camcc CAM_CC_IFE_LITE_CLK_SRC>, <&camcc CAM_CC_IFE_LITE_AHB_CLK>, <&camcc CAM_CC_IFE_LITE_CLK>;
			clock-rates = <0x17d78400 0x0 0x0 0x0 0x17d78400 0x0 0x0 0x17d78400 0x0 0x0 0x0 0x1c9c3800 0x0 0x0 0x17d78400 0x0 0x0 0x0 0x1c9c3800 0x0 0x0 0x17d78400 0x0 0x0 0x0 0x1c9c3800 0x0 0x0>;
			clock-cntl-level = "lowsvs", "svs", "svs_l1", "turbo";
			src-clock-name = "ife_csid_clk_src";
			clock-control-debugfs = "true";
			status = "ok";
			power-domains = <&camcc TITAN_TOP_GDSC>;
			power-domain-names = "camss";
		};
		q2cam_3ae: qcom,ife0@acb4000 {
			cell-index = <0x0>;
			compatible = "qcom,vfe480";
			reg-names = "ife", "cam_camnoc";
			reg = <0x0 0xacb4000 0x0 0xd000 0x0 0xac42000 0x0 0x8000>;
			reg-cam-base = <0xb4000 0x42000>;
			interrupt-names = "ife";
			interrupts = <0x0 0x1d1 0x1>;
			regulator-names = "camss", "ife0";
			clock-names = "ife_0_ahb", "ife_0_areg", "ife_clk_src", "ife_clk", "ife_axi_clk";
			clocks = <&camcc CAM_CC_IFE_0_AHB_CLK>, <&camcc CAM_CC_IFE_0_AREG_CLK>, <&camcc CAM_CC_IFE_0_CLK_SRC>, <&camcc CAM_CC_IFE_0_CLK>, <&camcc CAM_CC_IFE_0_AXI_CLK>;
			clock-rates = <0x0 0x5f5e100 0x14dc9380 0x0 0x0 0x0 0xbebc200 0x1c4fecc0 0x0 0x0 0x0 0x11e1a300 0x22551000 0x0 0x0 0x0 0x17d78400 0x2aea5400 0x0 0x0>;
			clock-cntl-level = "lowsvs", "svs", "svs_l1", "turbo";
			src-clock-name = "ife_clk_src";
			scl-clk-names = "ife_0_areg";
			clock-control-debugfs = "true";
			clock-names-option = "ife_dsp_clk";
			clocks-option = <0x58 0x31>;
			clock-rates-option = <0x2aea5400>;
			ubwc-static-cfg = <0x1026 0x1036>;
			status = "ok";
			power-domains = <&camcc TITAN_TOP_GDSC>, <&camcc IFE_0_GDSC>;
			power-domain-names = "camss", "ife0";
		};
		q2cam_3b0: qcom,ife1@acc3000 {
			cell-index = <0x1>;
			compatible = "qcom,vfe480";
			reg-names = "ife", "cam_camnoc";
			reg = <0x0 0xacc3000 0x0 0xd000 0x0 0xac42000 0x0 0x8000>;
			reg-cam-base = <0xc3000 0x42000>;
			interrupt-names = "ife";
			interrupts = <0x0 0x1d3 0x1>;
			regulator-names = "camss", "ife1";
			clock-names = "ife_1_ahb", "ife_1_areg", "ife_clk_src", "ife_clk", "ife_axi_clk";
			clocks = <&camcc CAM_CC_IFE_1_AHB_CLK>, <&camcc CAM_CC_IFE_1_AREG_CLK>, <&camcc CAM_CC_IFE_1_CLK_SRC>, <&camcc CAM_CC_IFE_1_CLK>, <&camcc CAM_CC_IFE_1_AXI_CLK>;
			clock-rates = <0x0 0x5f5e100 0x14dc9380 0x0 0x0 0x0 0xbebc200 0x1c4fecc0 0x0 0x0 0x0 0x11e1a300 0x22551000 0x0 0x0 0x0 0x17d78400 0x2aea5400 0x0 0x0>;
			clock-cntl-level = "lowsvs", "svs", "svs_l1", "turbo";
			src-clock-name = "ife_clk_src";
			scl-clk-names = "ife_1_areg";
			clock-control-debugfs = "true";
			clock-names-option = "ife_dsp_clk";
			clocks-option = <0x58 0x3a>;
			clock-rates-option = <0x2aea5400>;
			ubwc-static-cfg = <0x1026 0x1036>;
			status = "ok";
			power-domains = <&camcc TITAN_TOP_GDSC>, <&camcc IFE_1_GDSC>;
			power-domain-names = "camss", "ife1";
		};
		q2cam_3b2: qcom,ife-lite0@acd9000 {
			cell-index = <0x2>;
			compatible = "qcom,vfe-lite480";
			reg-names = "ife-lite";
			reg = <0x0 0xacd9000 0x0 0x2200>;
			reg-cam-base = <0xd9000>;
			interrupt-names = "ife-lite";
			interrupts = <0x0 0x1d5 0x1>;
			regulator-names = "camss";
			clock-names = "ife_lite_ahb", "ife_lite_axi", "ife_clk_src", "ife_clk";
			clocks = <&camcc CAM_CC_IFE_LITE_AHB_CLK>, <&camcc CAM_CC_IFE_LITE_AXI_CLK>, <&camcc CAM_CC_IFE_LITE_CLK_SRC>, <&camcc CAM_CC_IFE_LITE_CLK>;
			clock-rates = <0x0 0x0 0x17d78400 0x0 0x0 0x0 0x1c9c3800 0x0 0x0 0x0 0x1c9c3800 0x0 0x0 0x0 0x1c9c3800 0x0>;
			clock-cntl-level = "lowsvs", "svs", "svs_l1", "turbo";
			src-clock-name = "ife_clk_src";
			clock-control-debugfs = "true";
			status = "ok";
			power-domains = <&camcc TITAN_TOP_GDSC>;
			power-domain-names = "camss";
		};
		q2cam_3b4: qcom,ife-lite1@acdb200 {
			cell-index = <0x3>;
			compatible = "qcom,vfe-lite480";
			reg-names = "ife-lite";
			reg = <0x0 0xacdb200 0x0 0x2200>;
			reg-cam-base = <0xdb200>;
			interrupt-names = "ife-lite";
			interrupts = <0x0 0x168 0x1>;
			regulator-names = "camss";
			clock-names = "ife_lite_ahb", "ife_lite_axi", "ife_clk_src", "ife_clk";
			clocks = <&camcc CAM_CC_IFE_LITE_AHB_CLK>, <&camcc CAM_CC_IFE_LITE_AXI_CLK>, <&camcc CAM_CC_IFE_LITE_CLK_SRC>, <&camcc CAM_CC_IFE_LITE_CLK>;
			clock-rates = <0x0 0x0 0x17d78400 0x0 0x0 0x0 0x1c9c3800 0x0 0x0 0x0 0x1c9c3800 0x0 0x0 0x0 0x1c9c3800 0x0>;
			clock-cntl-level = "lowsvs", "svs", "svs_l1", "turbo";
			src-clock-name = "ife_clk_src";
			clock-control-debugfs = "true";
			status = "ok";
			power-domains = <&camcc TITAN_TOP_GDSC>;
			power-domain-names = "camss";
		};
		q2cam_3b6: qcom,ife-lite2@acdd400 {
			cell-index = <0x4>;
			compatible = "qcom,vfe-lite480";
			reg-names = "ife-lite";
			reg = <0x0 0xacdd400 0x0 0x2200>;
			reg-cam-base = <0xdd400>;
			interrupt-names = "ife-lite";
			interrupts = <0x0 0x10a 0x1>;
			regulator-names = "camss";
			clock-names = "ife_lite_ahb", "ife_lite_axi", "ife_clk_src", "ife_clk";
			clocks = <&camcc CAM_CC_IFE_LITE_AHB_CLK>, <&camcc CAM_CC_IFE_LITE_AXI_CLK>, <&camcc CAM_CC_IFE_LITE_CLK_SRC>, <&camcc CAM_CC_IFE_LITE_CLK>;
			clock-rates = <0x0 0x0 0x17d78400 0x0 0x0 0x0 0x1c9c3800 0x0 0x0 0x0 0x1c9c3800 0x0 0x0 0x0 0x1c9c3800 0x0>;
			clock-cntl-level = "lowsvs", "svs", "svs_l1", "turbo";
			src-clock-name = "ife_clk_src";
			clock-control-debugfs = "true";
			status = "ok";
			power-domains = <&camcc TITAN_TOP_GDSC>;
			power-domain-names = "camss";
		};
		q2cam_3b8: qcom,ife-lite3@acdf600 {
			cell-index = <0x5>;
			compatible = "qcom,vfe-lite480";
			reg-names = "ife-lite";
			reg = <0x0 0xacdf600 0x0 0x2200>;
			reg-cam-base = <0xdf600>;
			interrupt-names = "ife-lite";
			interrupts = <0x0 0x1c2 0x1>;
			regulator-names = "camss";
			clock-names = "ife_lite_ahb", "ife_lite_axi", "ife_clk_src", "ife_clk";
			clocks = <&camcc CAM_CC_IFE_LITE_AHB_CLK>, <&camcc CAM_CC_IFE_LITE_AXI_CLK>, <&camcc CAM_CC_IFE_LITE_CLK_SRC>, <&camcc CAM_CC_IFE_LITE_CLK>;
			clock-rates = <0x0 0x0 0x17d78400 0x0 0x0 0x0 0x1c9c3800 0x0 0x0 0x0 0x1c9c3800 0x0 0x0 0x0 0x1c9c3800 0x0>;
			clock-cntl-level = "lowsvs", "svs", "svs_l1", "turbo";
			src-clock-name = "ife_clk_src";
			clock-control-debugfs = "true";
			status = "ok";
			power-domains = <&camcc TITAN_TOP_GDSC>;
			power-domain-names = "camss";
		};
		q2cam_3ba: qcom,ife-lite4@ace1800 {
			cell-index = <0x6>;
			compatible = "qcom,vfe-lite480";
			reg-names = "ife-lite";
			reg = <0x0 0xace1800 0x0 0x2200>;
			reg-cam-base = <0xe1800>;
			interrupt-names = "ife-lite";
			interrupts = <0x0 0x1c4 0x1>;
			regulator-names = "camss";
			clock-names = "ife_lite_ahb", "ife_lite_axi", "ife_clk_src", "ife_clk";
			clocks = <&camcc CAM_CC_IFE_LITE_AHB_CLK>, <&camcc CAM_CC_IFE_LITE_AXI_CLK>, <&camcc CAM_CC_IFE_LITE_CLK_SRC>, <&camcc CAM_CC_IFE_LITE_CLK>;
			clock-rates = <0x0 0x0 0x17d78400 0x0 0x0 0x0 0x1c9c3800 0x0 0x0 0x0 0x1c9c3800 0x0 0x0 0x0 0x1c9c3800 0x0>;
			clock-cntl-level = "lowsvs", "svs", "svs_l1", "turbo";
			src-clock-name = "ife_clk_src";
			clock-control-debugfs = "true";
			status = "ok";
			power-domains = <&camcc TITAN_TOP_GDSC>;
			power-domain-names = "camss";
		};
		qcom,cpas-cdm1@acb4200 {
			cell-index = <0x1>;
			compatible = "qcom,cam480-cpas-cdm1";
			label = "cpas-cdm";
			reg = <0x0 0xacb4200 0x0 0x1000>;
			reg-names = "cpas-cdm";
			reg-cam-base = <0xb4200>;
			interrupts = <0x0 0x1c8 0x1>;
			interrupt-names = "cpas-cdm";
			regulator-names = "camss";
			clock-names = "cam_cc_cpas_slow_ahb_clk", "cam_cc_cpas_ahb_clk";
			clocks = <&camcc CAM_CC_SLOW_AHB_CLK_SRC>, <&camcc CAM_CC_CPAS_AHB_CLK>;
			clock-rates = <0x0 0x0>;
			clock-cntl-level = "svs";
			cdm-client-names = "ife0";
			status = "disabled";
			power-domains = <&camcc TITAN_TOP_GDSC>;
			power-domain-names = "camss";
		};
		qcom,cpas-cdm2@acc3200 {
			cell-index = <0x2>;
			compatible = "qcom,cam480-cpas-cdm2";
			label = "cpas-cdm";
			reg = <0x0 0xacc3200 0x0 0x1000>;
			reg-names = "cpas-cdm";
			reg-cam-base = <0xc3200>;
			interrupts = <0x0 0x11f 0x1>;
			interrupt-names = "cpas-cdm";
			regulator-names = "camss";
			clock-names = "cam_cc_cpas_slow_ahb_clk", "cam_cc_cpas_ahb_clk";
			clocks = <&camcc CAM_CC_SLOW_AHB_CLK_SRC>, <&camcc CAM_CC_CPAS_AHB_CLK>;
			clock-rates = <0x0 0x0>;
			clock-cntl-level = "svs";
			cdm-client-names = "ife1";
			status = "disabled";
			power-domains = <&camcc TITAN_TOP_GDSC>;
			power-domain-names = "camss";
		};

		qcom,cam-cpas@ac40000 {
			cell-index = <0x0>;
			compatible = "qcom,cam-cpas";
			label = "cpas";
			arch-compat = "cpas_top";
			status = "okay";
			reg-names = "cam_cpas_top", "cam_camnoc";
			reg = <0x0 0xac40000 0x0 0x1000 0x0 0xac42000 0x0 0x8000>;
			reg-cam-base = <0x40000 0x42000>;
			interrupt-names = "cpas_camnoc";
			interrupts = <0x0 0x1cb 0x1>;
			camnoc-axi-min-ib-bw = <0xb2d05e00>;
			regulator-names = "camss-vdd";
			clock-names = "gcc_ahb_clk", "gcc_axi_hf_clk", "gcc_axi_sf_clk", "slow_ahb_clk_src", "cpas_ahb_clk", "cpas_core_ahb_clk", "camnoc_axi_clk_src", "camnoc_axi_clk";
			/* gcc_ahb_clk: always on in mainline gcc (not handed out); the board XO stands in */
			clocks = <&xo_board>, <&gcc GCC_CAMERA_HF_AXI_CLK>, <&gcc GCC_CAMERA_SF_AXI_CLK>, <&camcc CAM_CC_SLOW_AHB_CLK_SRC>, <&camcc CAM_CC_CPAS_AHB_CLK>, <&camcc CAM_CC_CORE_AHB_CLK>, <&camcc CAM_CC_CAMNOC_AXI_CLK_SRC>, <&camcc CAM_CC_CAMNOC_AXI_CLK>;
			src-clock-name = "camnoc_axi_clk_src";
			clock-rates = <0x0 0x0 0x0 0x0 0x0 0x0 0x0 0x0 0x0 0x0 0x0 0x124f800 0x0 0x0 0x124f800 0x0 0x0 0x0 0x0 0x4c4b400 0x0 0x0 0x11e1a300 0x0 0x0 0x0 0x0 0x4c4b400 0x0 0x0 0x17d78400 0x0 0x0 0x0 0x0 0x4c4b400 0x0 0x0 0x17d78400 0x0 0x0 0x0 0x0 0x4c4b400 0x0 0x0 0x17d78400 0x0 0x0 0x0 0x0 0x4c4b400 0x0 0x0 0x17d78400 0x0 0x0 0x0 0x0 0x4c4b400 0x0 0x0 0x1c9c3800 0x0>;
			clock-cntl-level = "suspend", "minsvs", "lowsvs", "svs", "svs_l1", "nominal", "nominal_l1", "turbo";
			control-camnoc-axi-clk;
			camnoc-bus-width = <0x20>;
			camnoc-axi-clk-bw-margin-perc = <0x14>;
			qcom,msm-bus,name = "cam_ahb";
			qcom,msm-bus,num-cases = <0x8>;
			qcom,msm-bus,num-paths = <0x1>;
			qcom,msm-bus,vectors-KBps = <0x1 0x24d 0x0 0x0 0x1 0x24d 0x0 0x12c00 0x1 0x24d 0x0 0x12c00 0x1 0x24d 0x0 0x249f0 0x1 0x24d 0x0 0x249f0 0x1 0x24d 0x0 0x493e0 0x1 0x24d 0x0 0x493e0 0x1 0x24d 0x0 0x493e0>;
			vdd-corners = <0x10 0x30 0x40 0x80 0xc0 0x100 0x140 0x150 0x180 0x1a0>;
			vdd-corner-ahb-mapping = "suspend", "minsvs", "lowsvs", "svs", "svs_l1", "nominal", "nominal", "nominal", "turbo", "turbo";
			client-id-based;
			client-names = "csiphy0", "csiphy1", "csiphy2", "csiphy3", "csiphy4", "csiphy5", "cci0", "cci1", "csid0", "csid1", "csid2", "csid3", "csid4", "csid5", "csid6", "ife0", "ife1", "ife2", "ife3", "ife4", "ife5", "ife6", "custom0", "ipe0", "cam-cdm-intf0", "cpas-cdm0", "bps0", "icp0", "jpeg-dma0", "jpeg-enc0", "fd0";
			power-domains = <&camcc TITAN_TOP_GDSC>;
			power-domain-names = "camss-vdd";
			/* The bus votes by name (qcom,msm-bus,name), on the paths mainline's CAMSS names the same way */
			interconnects = <&gem_noc MASTER_AMPSS_M0 0 &config_noc SLAVE_CAMERA_CFG 0>,
					<&mmss_noc MASTER_CAMNOC_HF 0 &mc_virt SLAVE_EBI_CH0 0>,
					<&mmss_noc MASTER_CAMNOC_SF 0 &mc_virt SLAVE_EBI_CH0 0>,
					<&mmss_noc MASTER_CAMNOC_ICP 0 &mc_virt SLAVE_EBI_CH0 0>;
			interconnect-names = "cam_ahb", "cam_hf_0_mnoc", "cam_sf_0_mnoc", "cam_sf_icp_mnoc";
			camera-bus-nodes {
				level3-nodes {
					level-index = <0x3>;
					q2cam_169: level3-rt0-rd-wr-sum {
						cell-index = <0x0>;
						node-name = "level3-rt0-rd-wr-sum";
						traffic-merge-type = <0x0>;
						qcom,axi-port-name = "cam_hf_0";
						ib-bw-voting-needed;
						qcom,axi-port-mnoc {
							qcom,msm-bus,name = "cam_hf_0_mnoc";
							qcom,msm-bus-vector-dyn-vote;
							qcom,msm-bus,num-cases = <0x2>;
							qcom,msm-bus,num-paths = <0x1>;
							qcom,msm-bus,vectors-KBps = <0xaa 0x200 0x0 0x0 0xaa 0x200 0x0 0x0>;
						};
					};
					q2cam_16a: level3-nrt0-rd-wr-sum {
						cell-index = <0x1>;
						node-name = "level3-nrt0-rd-wr-sum";
						traffic-merge-type = <0x0>;
						qcom,axi-port-name = "cam_sf_0";
						qcom,axi-port-mnoc {
							qcom,msm-bus,name = "cam_sf_0_mnoc";
							qcom,msm-bus-vector-dyn-vote;
							qcom,msm-bus,num-cases = <0x2>;
							qcom,msm-bus,num-paths = <0x1>;
							qcom,msm-bus,vectors-KBps = <0x89 0x200 0x0 0x0 0x89 0x200 0x0 0x0>;
						};
					};
					q2cam_16b: level3-nrt1-rd-wr-sum {
						cell-index = <0x2>;
						node-name = "level3-nrt1-rd-wr-sum";
						traffic-merge-type = <0x0>;
						qcom,axi-port-name = "cam_sf_icp";
						qcom,axi-port-mnoc {
							qcom,msm-bus,name = "cam_sf_icp_mnoc";
							qcom,msm-bus-vector-dyn-vote;
							qcom,msm-bus,num-cases = <0x2>;
							qcom,msm-bus,num-paths = <0x1>;
							qcom,msm-bus,vectors-KBps = <0xab 0x200 0x0 0x0 0xab 0x200 0x0 0x0>;
						};
					};
				};
				level2-nodes {
					level-index = <0x2>;
					camnoc-max-needed;
					q2cam_16c: level2-rt0-wr {
						cell-index = <0x3>;
						node-name = "level2-rt0-wr";
						parent-node = <&q2cam_169>;
						traffic-merge-type = <0x1>;
					};
					q2cam_16d: level2-rt0-rd {
						cell-index = <0x4>;
						node-name = "level2-rt0-rd";
						parent-node = <&q2cam_169>;
						traffic-merge-type = <0x1>;
					};
					q2cam_16e: level2-nrt0-wr {
						cell-index = <0x5>;
						node-name = "level2-nrt0-wr";
						parent-node = <&q2cam_16a>;
						traffic-merge-type = <0x1>;
					};
					q2cam_16f: level2-nrt0-rd {
						cell-index = <0x6>;
						node-name = "level2-nrt0-rd";
						parent-node = <&q2cam_16a>;
						traffic-merge-type = <0x1>;
					};
					q2cam_178: level2-nrt1-rd {
						cell-index = <0x7>;
						node-name = "level2-nrt1-rd";
						parent-node = <&q2cam_16b>;
						traffic-merge-type = <0x0>;
						bus-width-factor = <0x4>;
					};
				};
				level1-nodes {
					level-index = <0x1>;
					camnoc-max-needed;
					q2cam_170: level1-rt0-wr0 {
						cell-index = <0x8>;
						node-name = "level1-rt0-wr0";
						parent-node = <&q2cam_16c>;
						traffic-merge-type = <0x0>;
					};
					q2cam_171: level1-rt0-wr1 {
						cell-index = <0x9>;
						node-name = "level1-rt0-wr1";
						parent-node = <&q2cam_16c>;
						traffic-merge-type = <0x0>;
					};
					q2cam_172: level1-rt0-rd0 {
						cell-index = <0xa>;
						node-name = "level1-rt0-rd0";
						parent-node = <&q2cam_16d>;
						traffic-merge-type = <0x0>;
					};
					q2cam_173: level1-rt0-wr2 {
						cell-index = <0xb>;
						node-name = "level1-rt0-wr2";
						parent-node = <&q2cam_16c>;
						traffic-merge-type = <0x0>;
					};
					q2cam_174: level1-nrt0-wr0 {
						cell-index = <0xc>;
						node-name = "level1-nrt0-wr0";
						parent-node = <&q2cam_16e>;
						traffic-merge-type = <0x0>;
					};
					q2cam_175: level1-nrt0-rd0 {
						cell-index = <0xd>;
						node-name = "level1-nrt0-rd0";
						parent-node = <&q2cam_16f>;
						traffic-merge-type = <0x0>;
					};
					q2cam_176: level1-nrt0-wr1 {
						cell-index = <0xe>;
						node-name = "level1-nrt0-wr1";
						parent-node = <&q2cam_16e>;
						traffic-merge-type = <0x0>;
					};
					q2cam_177: level1-nrt0-rd2 {
						cell-index = <0xf>;
						node-name = "level1-nrt0-rd2";
						parent-node = <&q2cam_16f>;
						traffic-merge-type = <0x0>;
					};
				};
				level0-nodes {
					level-index = <0x0>;
					q2cam_391: ife0-ubwc-stats-wr {
						cell-index = <0x10>;
						node-name = "ife0-ubwc-stats-wr";
						client-name = "ife0";
						traffic-data = <0x102>;
						traffic-transaction-type = <0x1>;
						constituent-paths = <0x1 0x2 0x3>;
						parent-node = <&q2cam_170>;
					};
					q2cam_392: ife1-ubwc-stats-wr {
						cell-index = <0x11>;
						node-name = "ife1-ubwc-stats-wr";
						client-name = "ife1";
						traffic-data = <0x102>;
						traffic-transaction-type = <0x1>;
						constituent-paths = <0x1 0x2 0x3>;
						parent-node = <&q2cam_170>;
					};
					q2cam_393: ife0-linear-pdaf-wr {
						cell-index = <0x12>;
						node-name = "ife0-linear-pdaf-wr";
						client-name = "ife0";
						traffic-data = <0x101>;
						traffic-transaction-type = <0x1>;
						constituent-paths = <0x0 0x8>;
						parent-node = <&q2cam_171>;
					};
					q2cam_394: ife1-linear-pdaf-wr {
						cell-index = <0x13>;
						node-name = "ife1-linear-pdaf-wr";
						client-name = "ife1";
						traffic-data = <0x101>;
						traffic-transaction-type = <0x1>;
						constituent-paths = <0x0 0x8>;
						parent-node = <&q2cam_171>;
					};
					q2cam_395: ife2-rdi-all-wr {
						cell-index = <0x14>;
						node-name = "ife2-rdi-all-wr";
						client-name = "ife2";
						traffic-data = <0x105>;
						traffic-transaction-type = <0x1>;
						constituent-paths = <0x4 0x5 0x6 0x7>;
						parent-node = <&q2cam_171>;
					};
					q2cam_396: ife3-rdi-all-wr {
						cell-index = <0x15>;
						node-name = "ife3-rdi-all-wr";
						client-name = "ife3";
						traffic-data = <0x105>;
						traffic-transaction-type = <0x1>;
						constituent-paths = <0x4 0x5 0x6 0x7>;
						parent-node = <&q2cam_171>;
					};
					q2cam_397: ife4-rdi-all-wr {
						cell-index = <0x16>;
						node-name = "ife4-rdi-all-wr";
						client-name = "ife4";
						traffic-data = <0x105>;
						traffic-transaction-type = <0x1>;
						constituent-paths = <0x4 0x5 0x6 0x7>;
						parent-node = <&q2cam_171>;
					};
					q2cam_398: ife5-rdi-all-wr {
						cell-index = <0x17>;
						node-name = "ife5-rdi-all-wr";
						client-name = "ife5";
						traffic-data = <0x105>;
						traffic-transaction-type = <0x1>;
						constituent-paths = <0x4 0x5 0x6 0x7>;
						parent-node = <&q2cam_171>;
					};
					q2cam_399: ife0-rdi-all-rd {
						cell-index = <0x18>;
						node-name = "ife0-rdi-all-rd";
						client-name = "ife0";
						traffic-data = <0x105>;
						traffic-transaction-type = <0x0>;
						constituent-paths = <0x4 0x5 0x6 0x7>;
						parent-node = <&q2cam_172>;
					};
					q2cam_39a: ife1-rdi-all-rd {
						cell-index = <0x19>;
						node-name = "ife1-rdi-all-rd";
						client-name = "ife1";
						traffic-data = <0x105>;
						traffic-transaction-type = <0x0>;
						constituent-paths = <0x4 0x5 0x6 0x7>;
						parent-node = <&q2cam_172>;
					};
					q2cam_39b: custom0-all-rd {
						cell-index = <0x1a>;
						node-name = "custom0-all-rd";
						client-name = "custom0";
						traffic-data = <0x100>;
						traffic-transaction-type = <0x0>;
						parent-node = <&q2cam_172>;
					};
					q2cam_39c: ife0-rdi-pixel-raw-wr {
						cell-index = <0x1b>;
						node-name = "ife0-rdi-pixel-raw-wr";
						client-name = "ife0";
						traffic-data = <0x104>;
						traffic-transaction-type = <0x1>;
						constituent-paths = <0x4 0x5 0x6 0x9>;
						parent-node = <&q2cam_173>;
					};
					q2cam_39d: ife1-rdi-pixel-raw-wr {
						cell-index = <0x1c>;
						node-name = "ife1-rdi-pixel-raw-wr";
						client-name = "ife1";
						traffic-data = <0x104>;
						traffic-transaction-type = <0x1>;
						constituent-paths = <0x4 0x5 0x6 0x9>;
						parent-node = <&q2cam_173>;
					};
					q2cam_39e: ife6-rdi-all-wr {
						cell-index = <0x1d>;
						node-name = "ife6-rdi-all-wr";
						client-name = "ife6";
						traffic-data = <0x105>;
						traffic-transaction-type = <0x1>;
						constituent-paths = <0x4 0x5 0x6 0x7>;
						parent-node = <&q2cam_173>;
					};
					q2cam_39f: custom0-all-wr {
						cell-index = <0x1e>;
						node-name = "custom0-all-wr";
						client-name = "custom0";
						traffic-data = <0x100>;
						traffic-transaction-type = <0x1>;
						parent-node = <&q2cam_173>;
					};
					q2cam_3a0: ipe0-all-wr {
						cell-index = <0x1f>;
						node-name = "ipe0-all-wr";
						client-name = "ipe0";
						traffic-data = <0x100>;
						traffic-transaction-type = <0x1>;
						constituent-paths = <0x22 0x23 0x24>;
						parent-node = <&q2cam_174>;
					};
					q2cam_3a1: bps0-all-wr {
						cell-index = <0x20>;
						node-name = "bps0-all-wr";
						client-name = "bps0";
						traffic-data = <0x100>;
						traffic-transaction-type = <0x1>;
						parent-node = <&q2cam_174>;
					};
					q2cam_3a2: ipe0-ref-rd {
						cell-index = <0x21>;
						node-name = "ipe0-ref-rd";
						client-name = "ipe0";
						traffic-data = <0x21>;
						traffic-transaction-type = <0x0>;
						parent-node = <&q2cam_175>;
					};
					q2cam_3a3: bps0-all-rd {
						cell-index = <0x22>;
						node-name = "bps0-all-rd";
						client-name = "bps0";
						traffic-data = <0x100>;
						traffic-transaction-type = <0x0>;
						parent-node = <&q2cam_175>;
					};
					q2cam_3a4: ipe0-in-rd {
						cell-index = <0x23>;
						node-name = "ipe0-in-rd";
						client-name = "ipe0";
						traffic-data = <0x20>;
						traffic-transaction-type = <0x0>;
						parent-node = <&q2cam_16f>;
					};
					q2cam_3a5: jpeg-enc0-all-wr {
						cell-index = <0x24>;
						node-name = "jpeg-enc0-all-wr";
						client-name = "jpeg-enc0";
						traffic-data = <0x100>;
						traffic-transaction-type = <0x1>;
						parent-node = <&q2cam_176>;
					};
					q2cam_3a6: jpeg-dma0-all-wr {
						cell-index = <0x25>;
						node-name = "jpeg-dma0-all-wr";
						client-name = "jpeg-dma0";
						traffic-data = <0x100>;
						traffic-transaction-type = <0x1>;
						parent-node = <&q2cam_176>;
					};
					q2cam_3a7: jpeg-enc0-all-rd {
						cell-index = <0x26>;
						node-name = "jpeg-enc0-all-rd";
						client-name = "jpeg-enc0";
						traffic-data = <0x100>;
						traffic-transaction-type = <0x0>;
						parent-node = <&q2cam_177>;
					};
					q2cam_3a8: jpeg-dma0-all-rd {
						cell-index = <0x27>;
						node-name = "jpeg-dma0-all-rd";
						client-name = "jpeg-dma0";
						traffic-data = <0x100>;
						traffic-transaction-type = <0x0>;
						parent-node = <&q2cam_177>;
					};
					q2cam_3a9: fd0-all-wr {
						cell-index = <0x28>;
						node-name = "fd0-all-wr";
						client-name = "fd0";
						traffic-data = <0x100>;
						traffic-transaction-type = <0x1>;
						parent-node = <&q2cam_16e>;
					};
					q2cam_3aa: fd0-all-rd {
						cell-index = <0x29>;
						node-name = "fd0-all-rd";
						client-name = "fd0";
						traffic-data = <0x100>;
						traffic-transaction-type = <0x0>;
						parent-node = <&q2cam_16f>;
					};
					q2cam_3ab: cpas-cdm0-all-rd {
						cell-index = <0x2a>;
						node-name = "cpas-cdm0-all-rd";
						client-name = "cpas-cdm0";
						traffic-data = <0x100>;
						traffic-transaction-type = <0x0>;
						parent-node = <&q2cam_16f>;
					};
					q2cam_3ac: icp0-all-rd {
						cell-index = <0x2b>;
						node-name = "icp0-all-rd";
						client-name = "icp0";
						traffic-data = <0x100>;
						traffic-transaction-type = <0x0>;
						parent-node = <&q2cam_178>;
					};
				};
			};
		};
};

/* Pin states of the camera I2C buses and sensor clocks, from Quest OS's tree */
&tlmm {
	q2pin_160: cci0-active-state {
		mux {
			pins = "gpio101", "gpio102";
			function = "cci_i2c";
		};
		config {
			pins = "gpio101", "gpio102";
			bias-pull-up;
			drive-strength = <0x2>;
		};
	};
	q2pin_161: cci1-active-state {
		mux {
			pins = "gpio103", "gpio104";
			function = "cci_i2c";
		};
		config {
			pins = "gpio103", "gpio104";
			bias-pull-up;
			drive-strength = <0x2>;
		};
	};
	q2pin_162: cci0-suspend-state {
		mux {
			pins = "gpio101", "gpio102";
			function = "cci_i2c";
		};
		config {
			pins = "gpio101", "gpio102";
			bias-pull-down;
			drive-strength = <0x2>;
		};
	};
	q2pin_163: cci1-suspend-state {
		mux {
			pins = "gpio103", "gpio104";
			function = "cci_i2c";
		};
		config {
			pins = "gpio103", "gpio104";
			bias-pull-down;
			drive-strength = <0x2>;
		};
	};
	q2pin_164: cci2-active-state {
		mux {
			pins = "gpio105", "gpio106";
			function = "cci_i2c";
		};
		config {
			pins = "gpio105", "gpio106";
			bias-pull-up;
			drive-strength = <0x2>;
		};
	};
	q2pin_165: cci3-active-state {
		mux {
			pins = "gpio107", "gpio108";
			function = "cci_i2c";
		};
		config {
			pins = "gpio107", "gpio108";
			bias-pull-up;
			drive-strength = <0x2>;
		};
	};
	q2pin_166: cci2-suspend-state {
		mux {
			pins = "gpio105", "gpio106";
			function = "cci_i2c";
		};
		config {
			pins = "gpio105", "gpio106";
			bias-pull-down;
			drive-strength = <0x2>;
		};
	};
	q2pin_167: cci3-suspend-state {
		mux {
			pins = "gpio107", "gpio108";
			function = "cci_i2c";
		};
		config {
			pins = "gpio107", "gpio108";
			bias-pull-down;
			drive-strength = <0x2>;
		};
	};
	q2pin_320: cam-sensor-mclk0-active-state {
		mux {
			pins = "gpio94";
			function = "cam_mclk";
		};
		config {
			pins = "gpio94";
			bias-disable;
			drive-strength = <0x8>;
		};
	};
	q2pin_321: cam-sensor-mclk0-suspend-state {
		mux {
			pins = "gpio94";
			function = "cam_mclk";
		};
		config {
			pins = "gpio94";
			bias-pull-down;
			drive-strength = <0x8>;
		};
	};
	q2pin_322: cam-sensor-mclk1-active-state {
		mux {
			pins = "gpio95";
			function = "cam_mclk";
		};
		config {
			pins = "gpio95";
			bias-disable;
			drive-strength = <0x2>;
		};
	};
	q2pin_323: cam-sensor-mclk1-suspend-state {
		mux {
			pins = "gpio95";
			function = "cam_mclk";
		};
		config {
			pins = "gpio95";
			bias-pull-down;
			drive-strength = <0x2>;
		};
	};
	q2pin_324: cam-sensor-mclk2-active-state {
		mux {
			pins = "gpio96";
			function = "cam_mclk";
		};
		config {
			pins = "gpio96";
			bias-disable;
			drive-strength = <0x2>;
		};
	};
	q2pin_325: cam-sensor-mclk2-suspend-state {
		mux {
			pins = "gpio96";
			function = "cam_mclk";
		};
		config {
			pins = "gpio96";
			bias-pull-down;
			drive-strength = <0x2>;
		};
	};
	q2pin_326: cam-sensor-mclk3-active-state {
		mux {
			pins = "gpio97";
			function = "cam_mclk";
		};
		config {
			pins = "gpio97";
			bias-disable;
			drive-strength = <0x2>;
		};
	};
	q2pin_327: cam-sensor-mclk3-suspend-state {
		mux {
			pins = "gpio97";
			function = "cam_mclk";
		};
		config {
			pins = "gpio97";
			bias-pull-down;
			drive-strength = <0x2>;
		};
	};
};
